# CC430F5123 register map
Registers are 16-bit, read-write, reset 0x0 unless marked. A register's access mark holds for its fields unless they carry their own. Offsets are from the block's base; [hi:lo] are bit positions; {n}, {i} and the like mark numbered series.

## USCI_A0_UART_Mode
Base 0x00000000
0x5C0 UCA0CTLW0 — USCI A0 Control Word Register 0
0x5C0 UCA0CTL1 8-bit — USCI A0 Control Register 1
  [8:7] UCSSEL — USCI 0 Clock Source Select 1
    {v}=USCI 0 Clock Source: {v} (v=0..3)
  [5] UCRXEIE — RX Error interrupt enable
  [4] UCBRKIE — Break interrupt enable
  [3] UCDORM — Dormant (Sleep) Mode
  [2] UCTXADDR — Send next Data as Address
  [1] UCTXBRK — Send next Data as Break
  [0] UCSWRST — USCI Software Reset
0x5C1 UCA0CTL0 8-bit — USCI A0 Control Register 0
  [7] UCPEN — Async. Mode: Parity enable
  [6] UCPAR — Async. Mode: Parity 0:odd / 1:even
  [5] UCMSB — Async. Mode: MSB first 0:LSB / 1:MSB
  [4] UC7BIT — Async. Mode: Data Bits 0:8-bits / 1:7-bits
  [3] UCSPB — Async. Mode: Stop Bits 0:one / 1: two
  [3:2] UCMODE — Async. Mode: USCI Mode 1
    {v}=Sync. Mode: USCI Mode: {v} (v=0..3)
  [0] UCSYNC — Sync-Mode 0:UART-Mode / 1:SPI-Mode
0x5C6 UCA0BRW — USCI A0 Baud Word Rate 0
0x5C6 UCA0BR0 8-bit — USCI A0 Baud Rate 0
0x5C7 UCA0BR1 8-bit — USCI A0 Baud Rate 1
0x5C8 UCA0MCTL 8-bit — USCI A0 Modulation Control
  [10:7] UCBRF — USCI First Stage Modulation Select 3
    {v}=USCI First Stage Modulation: {v} (v=0..9); 10=USCI First Stage Modulation: A; 11=USCI First Stage Modulation: B; 12=USCI First Stage Modulation: C; 13=USCI First Stage Modulation: D; 14=USCI First Stage Modulation: E; 15=USCI First Stage Modulation: F
  [5:3] UCBRS — USCI Second Stage Modulation Select 2
    {v}=USCI Second Stage Modulation: {v} (v=0..7)
  [0] UCOS16 — USCI 16-times Oversampling enable
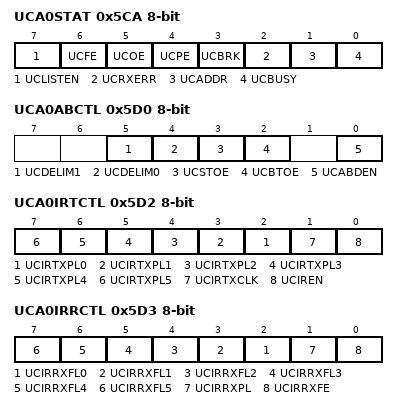
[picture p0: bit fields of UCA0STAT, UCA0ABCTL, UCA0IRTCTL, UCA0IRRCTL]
0x5CA UCA0STAT 8-bit — USCI A0 Status Register
  [7] UCLISTEN — USCI Listen mode
  [6] UCFE — USCI Frame Error Flag
  [5] UCOE — USCI Overrun Error Flag
  [4] UCPE — USCI Parity Error Flag
  [3] UCBRK — USCI Break received
  [2] UCRXERR — USCI RX Error Flag
  [1] UCADDR — USCI Address received Flag
  [0] UCBUSY — USCI Busy Flag
0x5CC UCA0RXBUF 8-bit — USCI A0 Receive Buffer
0x5CE UCA0TXBUF 8-bit — USCI A0 Transmit Buffer
0x5D0 UCA0ABCTL 8-bit — USCI A0 LIN Control
  [5] UCDELIM1 — Break Sync Delimiter 1
  [4] UCDELIM0 — Break Sync Delimiter 0
  [3] UCSTOE — Sync-Field Timeout error
  [2] UCBTOE — Break Timeout error
  [0] UCABDEN — Auto Baud Rate detect enable
0x5D2 UCA0IRCTL — USCI A0 IrDA Transmit Control
0x5D2 UCA0IRTCTL 8-bit — USCI A0 IrDA Transmit Control
  [n+2] UCIRTXPL{n} (n=0..5) — IRDA Transmit Pulse Length {n}
  [1] UCIRTXCLK — IRDA Transmit Pulse Clock Select
  [0] UCIREN — IRDA Encoder/Decoder enable
0x5D3 UCA0IRRCTL 8-bit — USCI A0 IrDA Receive Control
  [n+2] UCIRRXFL{n} (n=0..5) — IRDA Receive Filter Length {n}
  [1] UCIRRXPL — IRDA Receive Input Polarity
  [0] UCIRRXFE — IRDA Receive Filter enable
0x5DC UCA0ICTL — USCI A0 Interrupt Enable Register
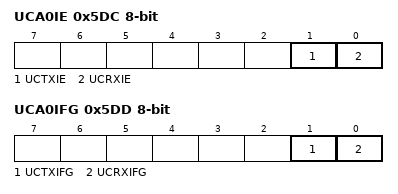
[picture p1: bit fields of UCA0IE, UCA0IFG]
0x5DC UCA0IE 8-bit — USCI A0 Interrupt Enable Register
  [1] UCTXIE — USCI Transmit Interrupt Enable
  [0] UCRXIE — USCI Receive Interrupt Enable
0x5DD UCA0IFG 8-bit — USCI A0 Interrupt Flags Register
  [1] UCTXIFG — USCI Transmit Interrupt Flag
  [0] UCRXIFG — USCI Receive Interrupt Flag
0x5DE UCA0IV — USCI A0 Interrupt Vector Register

## USCI_A0_SPI_Mode
Base 0x00000000
0x5C0 UCA0CTLW0_SPI — USCI A0 Control Word Register 0
0x5C0 UCA0CTL1_SPI 8-bit — USCI A0 Control Register 1
  [8:7] UCSSEL — USCI 1 Clock Source Select 1
    {v}=USCI 0 Clock Source: {v} (v=0..3)
  [0] UCSWRST — USCI Software Reset
0x5C1 UCA0CTL0_SPI 8-bit — USCI A0 Control Register 0
  [7] UCCKPH — Sync. Mode: Clock Phase
  [6] UCCKPL — Sync. Mode: Clock Polarity
  [5] UCMSB — Sync. Mode: MSB first 0:LSB / 1:MSB
  [4] UC7BIT — Sync. Mode: Data Bits 0:8-bits / 1:7-bits
  [3] UCMST — Sync. Mode: Master Select
  [3:2] UCMODE — Sync. Mode: USCI Mode 1
    {v}=Sync. Mode: USCI Mode: {v} (v=0..3)
  [0] UCSYNC — Sync-Mode 0:UART-Mode / 1:SPI-Mode
0x5C6 UCA0BRW_SPI — USCI A0 Baud Word Rate 0
0x5C6 UCA0BR0_SPI 8-bit — USCI A0 Baud Rate 0
0x5C7 UCA0BR1_SPI 8-bit — USCI A0 Baud Rate 1
0x5C8 UCA0MCTL_SPI 8-bit — USCI A0 Modulation Control
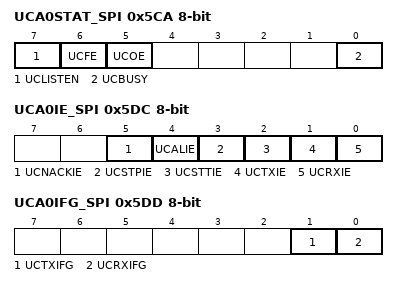
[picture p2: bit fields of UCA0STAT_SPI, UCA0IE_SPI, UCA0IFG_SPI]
0x5CA UCA0STAT_SPI 8-bit — USCI A0 Status Register
  [7] UCLISTEN — USCI Listen mode
  [6] UCFE — USCI Frame Error Flag
  [5] UCOE — USCI Overrun Error Flag
  [0] UCBUSY — USCI Busy Flag
0x5CC UCA0RXBUF_SPI 8-bit — USCI A0 Receive Buffer
0x5CE UCA0TXBUF_SPI 8-bit — USCI A0 Transmit Buffer
0x5DC UCA0ICTL_SPI — USCI A0 Interrupt Enable Register
0x5DC UCA0IE_SPI 8-bit — USCI A0 Interrupt Enable Register
  [5] UCNACKIE — NACK Condition interrupt enable
  [4] UCALIE — Arbitration Lost interrupt enable
  [3] UCSTPIE — STOP Condition interrupt enable
  [2] UCSTTIE — START Condition interrupt enable
  [1] UCTXIE — USCI Transmit Interrupt Enable
  [0] UCRXIE — USCI Receive Interrupt Enable
0x5DD UCA0IFG_SPI 8-bit — USCI A0 Interrupt Flags Register
  [1] UCTXIFG — USCI Transmit Interrupt Flag
  [0] UCRXIFG — USCI Receive Interrupt Flag
0x5DE UCA0IV_SPI — USCI A0 Interrupt Vector Register
